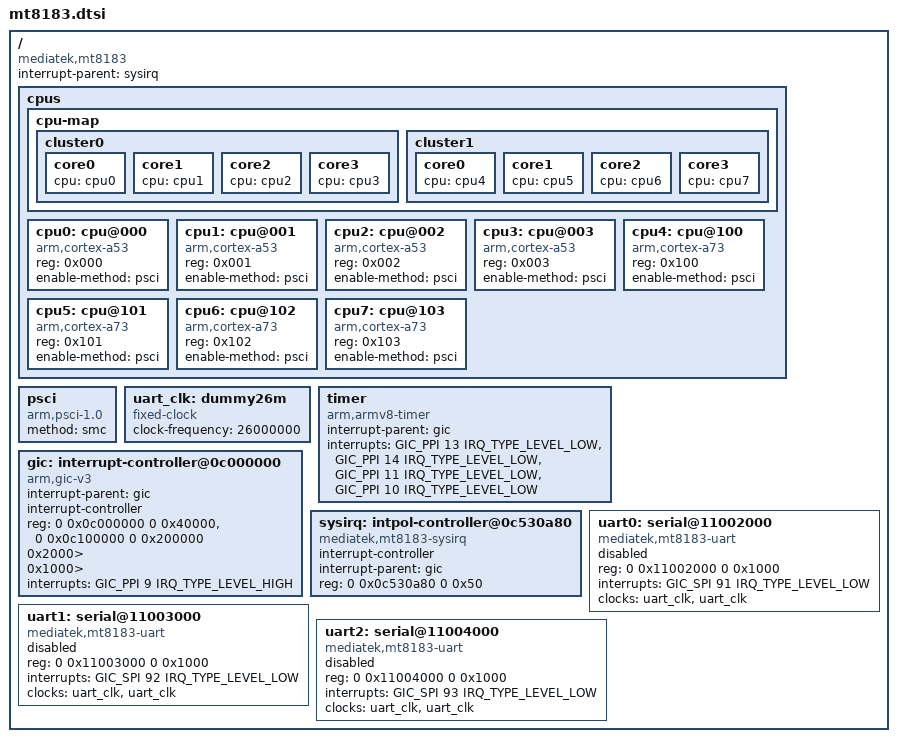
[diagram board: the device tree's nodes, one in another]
// SPDX-License-Identifier: (GPL-2.0 OR MIT)
/*
 * Copyright (c) 2018 MediaTek Inc.
 * Author: Ben Ho <ben.ho@mediatek.com>
 *	   Erin Lo <erin.lo@mediatek.com>
 */

#include <dt-bindings/interrupt-controller/irq.h>
#include <dt-bindings/interrupt-controller/arm-gic.h>

/ {
	compatible = "mediatek,mt8183";
	interrupt-parent = <&sysirq>;
	#address-cells = <2>;
	#size-cells = <2>;

	cpus {
		#address-cells = <1>;
		#size-cells = <0>;

		cpu-map {
			cluster0 {
				core0 {
					cpu = <&cpu0>;
				};
				core1 {
					cpu = <&cpu1>;
				};
				core2 {
					cpu = <&cpu2>;
				};
				core3 {
					cpu = <&cpu3>;
				};
			};

			cluster1 {
				core0 {
					cpu = <&cpu4>;
				};
				core1 {
					cpu = <&cpu5>;
				};
				core2 {
					cpu = <&cpu6>;
				};
				core3 {
					cpu = <&cpu7>;
				};
			};
		};

		cpu0: cpu@000 {
			device_type = "cpu";
			compatible = "arm,cortex-a53";
			reg = <0x000>;
			enable-method = "psci";
		};

		cpu1: cpu@001 {
			device_type = "cpu";
			compatible = "arm,cortex-a53";
			reg = <0x001>;
			enable-method = "psci";
		};

		cpu2: cpu@002 {
			device_type = "cpu";
			compatible = "arm,cortex-a53";
			reg = <0x002>;
			enable-method = "psci";
		};

		cpu3: cpu@003 {
			device_type = "cpu";
			compatible = "arm,cortex-a53";
			reg = <0x003>;
			enable-method = "psci";
		};

		cpu4: cpu@100 {
			device_type = "cpu";
			compatible = "arm,cortex-a73";
			reg = <0x100>;
			enable-method = "psci";
		};

		cpu5: cpu@101 {
			device_type = "cpu";
			compatible = "arm,cortex-a73";
			reg = <0x101>;
			enable-method = "psci";
		};

		cpu6: cpu@102 {
			device_type = "cpu";
			compatible = "arm,cortex-a73";
			reg = <0x102>;
			enable-method = "psci";
		};

		cpu7: cpu@103 {
			device_type = "cpu";
			compatible = "arm,cortex-a73";
			reg = <0x103>;
			enable-method = "psci";
		};
	};

	psci {
		compatible      = "arm,psci-1.0";
		method          = "smc";
	};

	uart_clk: dummy26m {
		compatible = "fixed-clock";
		clock-frequency = <26000000>;
		#clock-cells = <0>;
	};

	timer {
		compatible = "arm,armv8-timer";
		interrupt-parent = <&gic>;
		interrupts = <GIC_PPI 13 IRQ_TYPE_LEVEL_LOW>,
			     <GIC_PPI 14 IRQ_TYPE_LEVEL_LOW>,
			     <GIC_PPI 11 IRQ_TYPE_LEVEL_LOW>,
			     <GIC_PPI 10 IRQ_TYPE_LEVEL_LOW>;
	};

	gic: interrupt-controller@0c000000 {
		compatible = "arm,gic-v3";
		#interrupt-cells = <3>;
		interrupt-parent = <&gic>;
		interrupt-controller;
		reg = <0 0x0c000000 0 0x40000>,  /* GICD */
		      <0 0x0c100000 0 0x200000>; /* GICR */
		      <0 0x0c400000 0 0x2000>;   /* GICC */
		      <0 0x0c410000 0 0x1000>;   /* GICH */
		      <0 0x0c420000 0 0x2000>;   /* GICV */

		interrupts = <GIC_PPI 9 IRQ_TYPE_LEVEL_HIGH>;
	};

	sysirq: intpol-controller@0c530a80 {
		compatible = "mediatek,mt8183-sysirq",
			     "mediatek,mt6577-sysirq";
		interrupt-controller;
		#interrupt-cells = <3>;
		interrupt-parent = <&gic>;
		reg = <0 0x0c530a80 0 0x50>;
	};

	uart0: serial@11002000 {
		compatible = "mediatek,mt8183-uart",
			     "mediatek,mt6577-uart";
		reg = <0 0x11002000 0 0x1000>;
		interrupts = <GIC_SPI 91 IRQ_TYPE_LEVEL_LOW>;
		clocks = <&uart_clk>, <&uart_clk>;
		clock-names = "baud", "bus";
		status = "disabled";
	};

	uart1: serial@11003000 {
		compatible = "mediatek,mt8183-uart",
			     "mediatek,mt6577-uart";
		reg = <0 0x11003000 0 0x1000>;
		interrupts = <GIC_SPI 92 IRQ_TYPE_LEVEL_LOW>;
		clocks = <&uart_clk>, <&uart_clk>;
		clock-names = "baud", "bus";
		status = "disabled";
	};

	uart2: serial@11004000 {
		compatible = "mediatek,mt8183-uart",
			     "mediatek,mt6577-uart";
		reg = <0 0x11004000 0 0x1000>;
		interrupts = <GIC_SPI 93 IRQ_TYPE_LEVEL_LOW>;
		clocks = <&uart_clk>, <&uart_clk>;
		clock-names = "baud", "bus";
		status = "disabled";
	};
};
